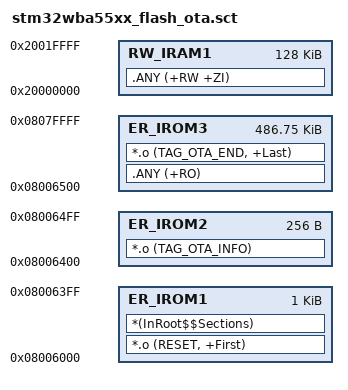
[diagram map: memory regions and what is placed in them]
; *************************************************************
; *** Scatter-Loading Description File generated by uVision ***
; *************************************************************

; Startup on Flash : 0x08006000 to 0x08006400
LR_IROM1 0x08006000 0x400
{    
  ; load address = execution address
  ER_IROM1      0x08006000 0x400  
  {  
    *.o (RESET, +First)
    *(InRoot$$Sections)
  }
}

; OTA INFO : 0x08006400 to 0x08006500
LR_IROM2 0x08006400 0x100
{
  ER_IROM2      0x08006400 0x100  
  {  
    *.o (TAG_OTA_INFO)
  }
}

; Application on Flash : 0x08006500 to 0x08080000
ER_IROM3 0x08006500 (0x80000 - 0x6500)
{
  ER_IROM3 0x08006500 (0x80000 - 0x6500)
  {  
    .ANY (+RO)
    *.o (TAG_OTA_END, +Last)
  }
  
  ; RW data RAM1 : 0x20000000 to 0x2001FFFF
  RW_IRAM1      0x20000000 0x00020000
  {  
   .ANY (+RW +ZI)
  }
}

; Download Zone on Flash : 0x08080000 to 0x080FC000

; Eeprom Zone on Flash : 0x080FC000 to 0x080FFFFF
